# R9A02G021 register map
Vendor: Renesas Electronics Corporation; Series: RISC-V; File version: 1.10.00 + 202304131714_CPU
CPU: other r0p0, little endian, no MPU, no FPU, VTOR, 4 interrupt priority bits, 32 interrupts
Registers are 8-bit, read-write, reset 0x0 unless marked. A register's access mark holds for its fields unless they carry their own. Offsets are from the block's base; [hi:lo] are bit positions; {n}, {i} and the like mark numbered series; 'fields as' and 'values as' point back to an identical list.

## SAU0 — Serial Array Unit 0
Base 0x40094000
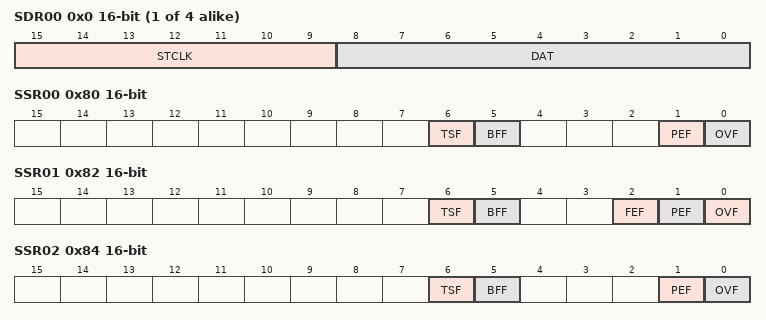
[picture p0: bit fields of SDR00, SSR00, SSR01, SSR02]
{0x0+2i} SDR0{i} (i=0..3) 16-bit — Serial Data Register 0{i}
  [15:9] STCLK — Transfer clock setting by dividing the operation clock
  [8:0] DAT — Data buffer for transmit and receive
0x80 SSR00 16-bit ro — Serial Status Register 00
  [6] TSF — Flag indicating the state of communications for channel n
    0=Communication is stopped or suspended; 1=Communication is in progress
  [5] BFF — Flag indicating the state of the buffer register for channel n
    0=Valid data is not stored in the SDRmn register; 1=Valid data is stored in the SDRmn register
  [1] PEF — Parity or ACK error detection flag of channel n
    0=No error occurs; 1=Parity error occurs (during UART reception) or ACK is not detected (during I2C transmission)
  [0] OVF — Overrun error detection flag of channel n
    0=No error occurs; 1=An error occurs
0x82 SSR01 16-bit ro — Serial Status Register 01
  [6] TSF — Flag indicating the state of communications for channel n
    values as SSR00.TSF
  [5] BFF — Flag indicating the state of the buffer register for channel n
    values as SSR00.BFF
  [2] FEF — Framing error detection flag of channel n
    0=No error occurs; 1=An error occurs (during UART reception)
  [1] PEF — Parity or ACK error detection flag of channel n
    values as SSR00.PEF
  [0] OVF — Overrun error detection flag of channel n
    0=No error occurs; 1=An error occurs
0x84 SSR02 16-bit ro — Serial Status Register 02
  fields as SSR00
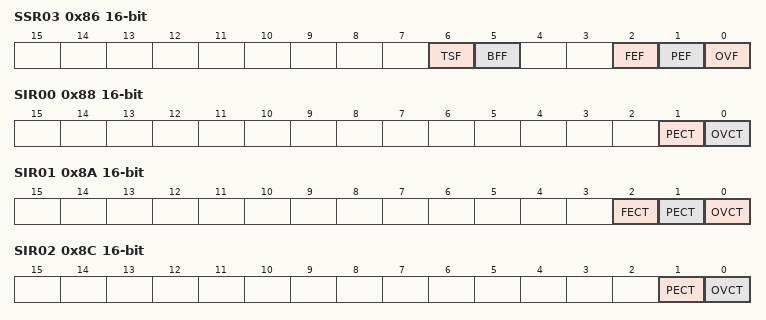
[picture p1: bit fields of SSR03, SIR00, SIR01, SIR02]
0x86 SSR03 16-bit ro — Serial Status Register 03
  fields as SSR01
0x88 SIR00 16-bit — Serial Flag Clear Trigger Register 00
  [1] PECT — Clear trigger of parity error flag of channel n
    0=Not cleared; 1=Clears the PEF flag of the SSRmn register to 0
  [0] OVCT — Clear trigger of overrun error flag of channel n
    0=Not cleared; 1=Clears the OVF flag of the SSRmn register to 0
0x8A SIR01 16-bit — Serial Flag Clear Trigger Register 01
  [2] FECT — Clear trigger of framing error flag of channel n
    0=Not cleared; 1=Clears the FEF flag of the SSRmn register to 0
  [1] PECT — Clear trigger of parity error flag of channel n
    values as SIR00.PECT
  [0] OVCT — Clear trigger of overrun error flag of channel n
    values as SIR00.OVCT
0x8C SIR02 16-bit — Serial Flag Clear Trigger Register 02
  fields as SIR00
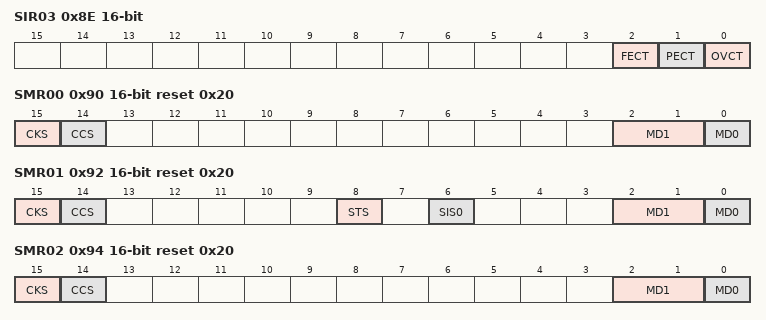
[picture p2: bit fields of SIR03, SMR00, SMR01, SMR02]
0x8E SIR03 16-bit — Serial Flag Clear Trigger Register 03
  fields as SIR01
0x90 SMR00 16-bit reset 0x20 — Serial Mode Register 00
  [15] CKS — Selection of operation clock (fMCK) of channel n
    0=Operation clock CKm0 set by the SPSm register; 1=Operation clock CKm1 set by the SPSm register
  [14] CCS — Selection of transfer clock (fTCLK) of channel n
    0=Divided operation clock fMCK specified by the CKS bit; 1=Clock input fSCK from the SCKp pin (slave transfer in simplified SPI mode)
  [2:1] MD1 — Setting of channel n operation mode
    0=Simplified SPI mode; 1=UART mode; 2=Simplified I2C mode; 3=Setting prohibited
  [0] MD0 — Selection of channel n interrupt source
    0=Transfer end interrupt; 1=Buffer empty interrupt (occurs when data is transferred from the SDRmn register to the shift register.)
0x92 SMR01 16-bit reset 0x20 — Serial Mode Register 01
  [15] CKS — Selection of operation clock (fMCK) of channel n
    values as SMR00.CKS
  [14] CCS — Selection of transfer clock (fTCLK) of channel n
    values as SMR00.CCS
  [8] STS — Selection of start trigger source
    0=Only software trigger is valid (selected for simplified SPI, UART transmission, and simplified I2C); 1=Valid edge of the RxDq pin (selected for UART reception)
  [6] SIS0 — Controls inversion of level of channel n receive data in UART mode
    0=Falling edge is detected as the start bit. The input communication data is captured as is.; 1=Rising edge is detected as the start bit. The input communication data is inverted and captured.
  [2:1] MD1 — Setting of channel n operation mode
    values as SMR00.MD1
  [0] MD0 — Selection of channel n interrupt source
    values as SMR00.MD0
0x94 SMR02 16-bit reset 0x20 — Serial Mode Register 02
  fields as SMR00
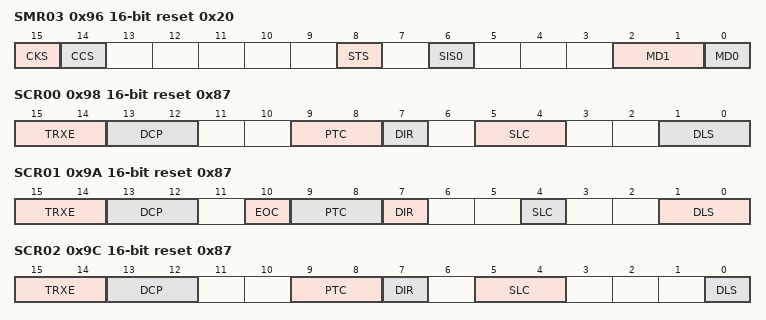
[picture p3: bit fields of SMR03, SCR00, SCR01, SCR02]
0x96 SMR03 16-bit reset 0x20 — Serial Mode Register 03
  fields as SMR01
0x98 SCR00 16-bit reset 0x87 — Serial Communication Operation Setting Register 00
  [15:14] TRXE — Setting of channel 0 operation mode
    0=Disable communication; 1=Reception only; 2=Transmission only; 3=Transmission and reception
  [13:12] DCP — Selection of data and clock phase in simplified SPI mode
    0=Type1 (SCK: inverted, Input timing: rising edge); 1=Type2 (SCK: non-inverted, Input timing: falling edge); 2=Type3 (SCK: inverted, Input timing: falling edge); 3=Type4 (SCK: non-inverted, Input timing: rising edge)
  [9:8] PTC — Setting of parity bit in UART mode
    0=Transmission: Does not output the parity bit Reception: Receives without parity; 1=Transmission: Outputs 0 parity Reception: No parity determination; 2=Transmission: Outputs even parity Reception: Determines as even parity; 3=Transmission: Outputs odd parity Reception: Determines as odd parity
  [7] DIR — Selection of data transfer sequence in simplified SPI and UART modes
    0=Inputs or outputs data with MSB first; 1=Inputs or outputs data with LSB first
  [5:4] SLC — Setting of stop bit in UART mode
    0=No stop bit; 1=Stop bit length = 1 bit; 2=Stop bit length = 2 bits; 3=Setting prohibited
  [1:0] DLS — Setting of data length in simplified SPI and UART modes
    0=Setting prohibited; 1=9-bit data length (stored in the DAT[8:0] bits of the SDRm0 register) (settable in UART mode only); 2=7-bit data length (stored in the DAT[6:0] bits of the SDRm0 register); 3=8-bit data length (stored in the DAT[7:0] bits of the SDRm0 register)
0x9A SCR01 16-bit reset 0x87 — Serial Communication Operation Setting Register 01
  [15:14] TRXE — Setting of channel 1 operation mode
    values as SCR00.TRXE
  [13:12] DCP — Selection of data and clock phase in simplified SPI mode
    values as SCR00.DCP
  [10] EOC — Mask control of error interrupt signal SAU0_INTSRE0 (m = 0), SAU1_INTSRE2 (m = 1)
    0=Disables generation of error interrupt SAU0_INTSRE0 (m = 0), SAU1_INTSRE2 (m = 1) (SAUm_ENDI1 is generated); 1=Enables generation of error interrupt SAU0_INTSRE0 (m = 0), SAU1_INTSRE2 (m = 1) (SAUm_ENDI1 is not generated if an error occurs)
  [9:8] PTC — Setting of parity bit in UART mode
    0=Transmission: Does not output the parity bit Reception: Receives without parity; 1=Transmission: Outputs 0 parity Reception: No parity judgment; 2=Transmission: Outputs even parity Reception: Determines as even parity; 3=Transmission: Outputs odd parity Reception: Determines as odd parity
  [7] DIR — Selection of data transfer sequence in simplified SPI and UART modes
    values as SCR00.DIR
  [4] SLC — Setting of stop bit in UART mode
    0=No stop bit; 1=Stop bit length = 1 bit
  [1:0] DLS — Setting of data length in simplified SPI and UART modes
    0=Setting prohibited; 1=9-bit data length (stored in the DAT[8:0] bits of the SDRm1 register) (settable in UART mode only); 2=7-bit data length (stored in the DAT[6:0] bits of the SDRm1 register); 3=8-bit data length (stored in the DAT[7:0] bits of the SDRm1 register)
0x9C SCR02 16-bit reset 0x87 — Serial Communication Operation Setting Register 02
  [15:14] TRXE — Setting of channel 2 operation mode
    0=Disables communication; 1=Reception only; 2=Transmission only; 3=Transmission and reception
  [13:12] DCP — Selection of data and clock phase in simplified SPI mode
    values as SCR00.DCP
  [9:8] PTC — Setting of parity bit in UART mode
    values as SCR01.PTC
  [7] DIR — Selection of data transfer sequence in simplified SPI and UART modes
    values as SCR00.DIR
  [5:4] SLC — Setting of stop bit in UART mode
    values as SCR00.SLC
  [0] DLS — Setting of data length in simplified SPI and UART modes
    0=7-bit data length (stored in the DAT[6:0] bits of the SDR02 register); 1=8-bit data length (stored in the DAT[7:0] bits of the SDR02 register)
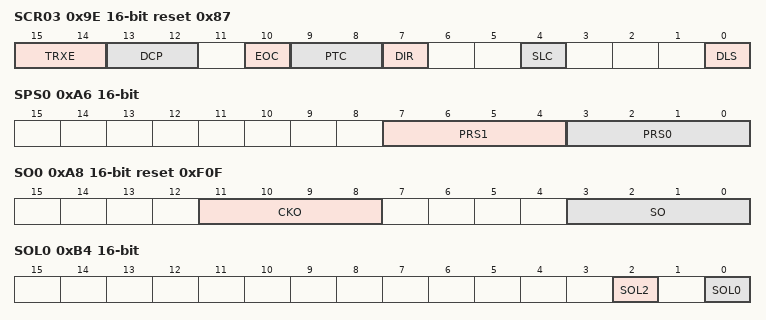
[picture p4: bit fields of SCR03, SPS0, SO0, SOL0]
0x9E SCR03 16-bit reset 0x87 — Serial Communication Operation Setting Register 03
  [15:14] TRXE — Setting of operation mode of channel 3
    values as SCR00.TRXE
  [13:12] DCP — Selection of data and clock phase in simplified SPI mode
    values as SCR00.DCP
  [10] EOC — Mask control of error interrupt signal SAU0_INTSRE1
    0=Disables generation of error interrupt SAU0_INTSRE1 (SAU0_ENDI3 is generated); 1=Enables generation of error interrupt SAU0_INTSRE1 (SAU0_ENDI3 is not generated if an error occurs)
  [9:8] PTC — Setting of parity bit in UART mode
    values as SCR00.PTC
  [7] DIR — Selection of data transfer sequence in simplified SPI and UART modes
    values as SCR00.DIR
  [4] SLC — Setting of stop bit in UART mode
    0=No stop bit; 1=Stop bit length = 1 bit
  [0] DLS — Setting of data length in simplified SPI and UART modes
    0=7-bit data length (stored in the DAT[6:0] bits of the SDR03 register); 1=8-bit data length (stored in the DAT[7:0] bits of the SDR03 register)
0xA0 SE0 16-bit ro — Serial Channel Enable Status Register 0
  [3:0] SE — Indication of whether operation of channel n is enabled or stopped.
    0=Operation stops; 1=Operation is enabled
0xA2 SS0 16-bit — Serial Channel Start Register 0
  [3:0] SS — Operation start trigger of channel n
    0=No trigger operation; 1=Set the SE0.SE[n] bit to 1 to place the channel in communications waiting state
0xA4 ST0 16-bit — Serial Channel Stop Register 0
  [3:0] ST — Operation stop trigger of channel n
    0=No trigger operation; 1=Clears the SE0.SE[n] bit to 0 and stops the communication operation
0xA6 SPS0 16-bit — Serial Clock Select Register 0
  [7:4] PRS1 — Selection of operation clock (CKm1)
    0=PCLKB; 1=PCLKB/2; {v}=PCLKB/{v+20} (v=2..9); {v}=PCLKB/{v+200} (v=10..15)
  [3:0] PRS0 — Selection of operation clock (CKm0)
    values as PRS1
0xA8 SO0 16-bit reset 0xF0F — Serial Output Register 0
  [11:8] CKO — Serial clock output of channel n
    0=Serial clock output value is 0; 1=Serial clock output value is 1
  [3:0] SO — Serial data output of channel n
    0=Serial data output value is 0; 1=Serial data output value is 1
0xAA SOE0 16-bit — Serial Output Enable Register 0
  [3:0] SOE — Serial output enable or stop of channel n
    0=Stops output by serial communication operation; 1=Enables output by serial communication operation
0xB4 SOL0 16-bit — Serial Output Level Register 0
  [2] SOL2 — Selects inversion of the level of the transmit data of channel 2 in UART mode
    0=Communication data is output as is; 1=Communication data is inverted and output
  [0] SOL0 — Selects inversion of the level of the transmit data of channel 0 in UART mode
    values as SOL2
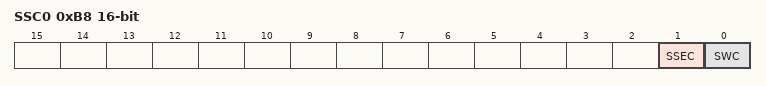
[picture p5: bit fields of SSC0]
0xB8 SSC0 16-bit — Serial Standby Control Register 0
  [1] SSEC — Selection of whether to enable or disable the generation of communication error interrupts in the Snooze mode
    0=Enable the generation of error interrupts SAUm_INTSREq; 1=Disable the generation of error interrupts SAUm_INTSREq
  [0] SWC — Setting of the Snooze mode
    0=Do not use the Snooze mode function; 1=Use the Snooze mode function
